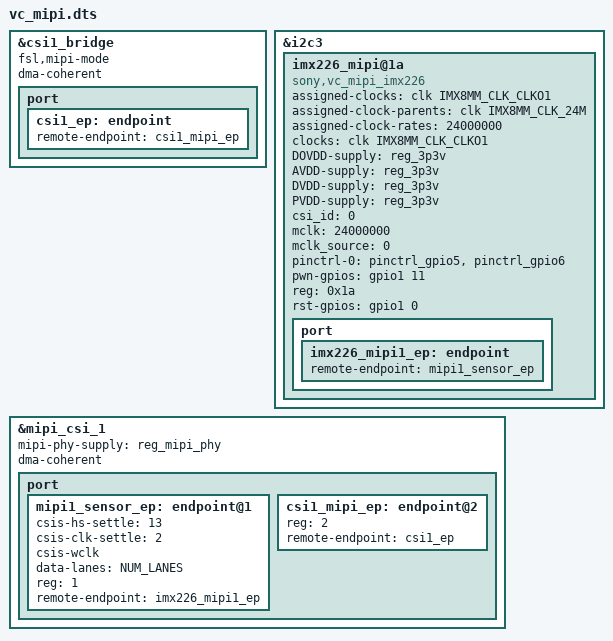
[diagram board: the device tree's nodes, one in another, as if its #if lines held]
/dts-v1/;

//#include "imx8mm-verdin.dtsi"
//#include "imx8mm-verdin-wifi.dtsi"
//#include "imx8mm-verdin-dev.dtsi"
#include "imx8mm-verdin-wifi-v1.1-dahlia.dts"

// Select VC MIPI driver - enable 1 driver only !
#define TORADEX_OV5640      0    /* CCC - Enable Toradex OV5640 driver                     */
#define VC_MIPI_OV9281      0    /* CCC - Enable VC MIPI OV9281 driver                     */
#define VC_MIPI_IMX_296_297 0    /* CCC - Enable VC MIPI IMX296,297 driver                 */
#define VC_MIPI_IMX         1    /* CCC - Enable VC MIPI IMX driver: all other IMX sensors */
// #define VC_MIPI_IMX226      0    /* CCC - Enable VC MIPI IMX226 driver      */

#define SCREENING_EAGLE_IMX258  0    /* CCC - Enable Screening Eagle IMX258 driver */


// / {
//     model = "Toradex Verdin iMX8M Mini WB on Verdin Development Board";
//     compatible = "toradex,verdin-imx8mm-wifi-dev",
//              "toradex,verdin-imx8mm-wifi",
//              "toradex,verdin-imx8mm",
//              "fsl,imx8mm";
// };


&csi1_bridge {
    fsl,mipi-mode;
    dma-coherent;
    status = "okay";

    port {
        csi1_ep: endpoint {
            remote-endpoint = <&csi1_mipi_ep>;
        };
    };
};

//----------------------------------------------------------------------------------
#if TORADEX_OV5640      /* [[[ - Toradex OV5640 driver  */
//----------------------------------------------------------------------------------
/* Verdin I2C_4_CSI */
&i2c3 {
    #address-cells = <1>;
    #size-cells = <0>;
    status = "okay";

    ov5640_mipi@3c {
        assigned-clocks = <&clk IMX8MM_CLK_CLKO1>;
        assigned-clock-parents = <&clk IMX8MM_CLK_24M>;
        assigned-clock-rates = <24000000>;
        compatible = "ovti,ov5640_mipi";
        clock-names = "csi_mclk";
        clocks = <&clk IMX8MM_CLK_CLKO1>;
        DOVDD-supply = <&reg_3p3v>;
        AVDD-supply = <&reg_3p3v>;
        DVDD-supply = <&reg_3p3v>;
        PVDD-supply = <&reg_3p3v>;
        csi_id = <0>;
        mclk = <24000000>;
        mclk_source = <0>;
        pinctrl-names = "default";
        pinctrl-0 = <&pinctrl_gpio5>, <&pinctrl_gpio6>;
        pwn-gpios = <&gpio1 11 GPIO_ACTIVE_HIGH>;
        reg = <0x3c>;
        rst-gpios = <&gpio1 0 GPIO_ACTIVE_HIGH>;
        status = "okay";

        port {
            ov5640_mipi1_ep: endpoint {
                remote-endpoint = <&mipi1_sensor_ep>;
            };
        };
    };
};

&mipi_csi_1 {
    mipi-phy-supply = <&reg_mipi_phy>;
    dma-coherent;
    status = "okay";

    port {
        #address-cells = <1>;
        #size-cells = <0>;

        mipi1_sensor_ep: endpoint@1 {
            csis-hs-settle = <13>;
            csis-clk-settle = <2>;
            csis-wclk;
            data-lanes = <2>;
            reg = <1>;
            remote-endpoint = <&ov5640_mipi1_ep>;
        };

        csi1_mipi_ep: endpoint@2 {
            reg = <2>;
            remote-endpoint = <&csi1_ep>;
        };
    };
};

//----------------------------------------------------------------------------------
#elif VC_MIPI_OV9281      /* ]]] [[[ - VC MIPI OV9281 driver */
//----------------------------------------------------------------------------------
&i2c3 {
    #address-cells = <1>;
    #size-cells = <0>;
    status = "okay";

    ov9281_mipi@60 {
        assigned-clocks = <&clk IMX8MM_CLK_CLKO1>;
        assigned-clock-parents = <&clk IMX8MM_CLK_24M>;
        assigned-clock-rates = <24000000>;
        compatible = "omnivision,vc_mipi_ov9281";
//        compatible = "ov,ov9281";
        clock-names = "csi_mclk";
        clocks = <&clk IMX8MM_CLK_CLKO1>;
        DOVDD-supply = <&reg_3p3v>;
        AVDD-supply = <&reg_3p3v>;
        DVDD-supply = <&reg_3p3v>;
        PVDD-supply = <&reg_3p3v>;
        csi_id = <0>;
        mclk = <24000000>;
        mclk_source = <0>;
        pinctrl-names = "default";
        pinctrl-0 = <&pinctrl_gpio5>, <&pinctrl_gpio6>;
        pwn-gpios = <&gpio1 11 GPIO_ACTIVE_HIGH>;
        reg = <0x60>;
        rst-gpios = <&gpio1 0 GPIO_ACTIVE_HIGH>;
        status = "okay";

        port {
            ov9281_mipi1_ep: endpoint {
                remote-endpoint = <&mipi1_sensor_ep>;
            };
        };
    };
};

&mipi_csi_1 {
    mipi-phy-supply = <&reg_mipi_phy>;
    dma-coherent;
    status = "okay";

    port {
        #address-cells = <1>;
        #size-cells = <0>;

        mipi1_sensor_ep: endpoint@1 {
            csis-hs-settle = <13>;
            csis-clk-settle = <2>;
            csis-wclk;
            data-lanes = <2>;
            reg = <1>;
            remote-endpoint = <&ov9281_mipi1_ep>;
        };

        csi1_mipi_ep: endpoint@2 {
            reg = <2>;
            remote-endpoint = <&csi1_ep>;
        };
    };
};

//----------------------------------------------------------------------------------
#elif VC_MIPI_IMX_296_297       /* ]]] [[[ - VC MIPI IMX296,297 driver  */
//----------------------------------------------------------------------------------
#define NUM_LANES  1    /* CCC - # of lanes: 1, 2 or 4  */
&i2c3 {
    #address-cells = <1>;
    #size-cells = <0>;
    status = "okay";

    imx_mipi@1a {
        assigned-clocks = <&clk IMX8MM_CLK_CLKO1>;
        assigned-clock-parents = <&clk IMX8MM_CLK_24M>;
        assigned-clock-rates = <24000000>;   // original

        compatible = "sony,vc_mipi_imx";
        clock-names = "csi_mclk";
        clocks = <&clk IMX8MM_CLK_CLKO1>;
        DOVDD-supply = <&reg_3p3v>;
        AVDD-supply = <&reg_3p3v>;
        DVDD-supply = <&reg_3p3v>;
        PVDD-supply = <&reg_3p3v>;
        csi_id = <0>;
        mclk = <24000000>;
        mclk_source = <0>;
        pinctrl-names = "default";
        pinctrl-0 = <&pinctrl_gpio5>, <&pinctrl_gpio6>;
        pwn-gpios = <&gpio1 11 GPIO_ACTIVE_HIGH>;
        reg = <0x1a>;
        rst-gpios = <&gpio1 0 GPIO_ACTIVE_HIGH>;
        status = "okay";

        port {
            imx_mipi1_ep: endpoint {
                remote-endpoint = <&mipi1_sensor_ep>;
            };
        };
    };
};

&mipi_csi_1 {
    mipi-phy-supply = <&reg_mipi_phy>;
//    clock-frequency = <333000000>;  // default
    dma-coherent;
    status = "okay";

    port {
        #address-cells = <1>;
        #size-cells = <0>;

        mipi1_sensor_ep: endpoint@1 {
            csis-hs-settle = <13>;
            csis-clk-settle = <2>;
            csis-wclk;
            data-lanes = <NUM_LANES>;
            reg = <1>;
            remote-endpoint = <&imx_mipi1_ep>;
        };

        csi1_mipi_ep: endpoint@2 {
            reg = <2>;
            remote-endpoint = <&csi1_ep>;
        };
    };
};

//----------------------------------------------------------------------------------
#elif VC_MIPI_IMX226        /* ]]] [[[ - VC MIPI IMX226 driver */
//----------------------------------------------------------------------------------
#define NUM_LANES  2    /* CCC - # of lanes: 2 or 4  */
&i2c3 {
    #address-cells = <1>;
    #size-cells = <0>;
    status = "okay";

    imx226_mipi@1a {
        assigned-clocks = <&clk IMX8MM_CLK_CLKO1>;
        assigned-clock-parents = <&clk IMX8MM_CLK_24M>;
        assigned-clock-rates = <24000000>;

//        assigned-clock-rates = <266000000>, <333000000>, <66000000>;
//        assigned-clock-rates = <266000000>, <150000000>, <66000000>;  // decreased rate, low FPS
//        assigned-clock-rates = <266000000>, <400000000>, <66000000>;  // ???

//        assigned-clock-rates = <133000000>, <100000000>, <66000000>;
//        assigned-clock-rates = <200000000>, <333000000>, <66000000>;

        compatible = "sony,vc_mipi_imx226";
        clock-names = "csi_mclk";
        clocks = <&clk IMX8MM_CLK_CLKO1>;
        DOVDD-supply = <&reg_3p3v>;
        AVDD-supply = <&reg_3p3v>;
        DVDD-supply = <&reg_3p3v>;
        PVDD-supply = <&reg_3p3v>;
        csi_id = <0>;
        mclk = <24000000>;
        mclk_source = <0>;
        pinctrl-names = "default";
        pinctrl-0 = <&pinctrl_gpio5>, <&pinctrl_gpio6>;
        pwn-gpios = <&gpio1 11 GPIO_ACTIVE_HIGH>;
        reg = <0x1a>;
        rst-gpios = <&gpio1 0 GPIO_ACTIVE_HIGH>;
        status = "okay";

        port {
            imx226_mipi1_ep: endpoint {
                remote-endpoint = <&mipi1_sensor_ep>;
            };
        };
    };
};

&mipi_csi_1 {
    mipi-phy-supply = <&reg_mipi_phy>;
//    clock-frequency = <166000000>;
//    clock-frequency = <333000000>;   // default
//      clock-frequency = <400000000>;
//    clock-frequency = <800000000>;
    dma-coherent;
    status = "okay";

    port {
        #address-cells = <1>;
        #size-cells = <0>;

        mipi1_sensor_ep: endpoint@1 {
            csis-hs-settle = <13>;
            csis-clk-settle = <2>;
            csis-wclk;
            data-lanes = <NUM_LANES>;
            reg = <1>;
            remote-endpoint = <&imx226_mipi1_ep>;
        };

        csi1_mipi_ep: endpoint@2 {
            reg = <2>;
            remote-endpoint = <&csi1_ep>;
        };
    };
};

//----------------------------------------------------------------------------------
#elif VC_MIPI_IMX        /* ]]] [[[ - VC MIPI IMX driver - all other IMX sesnors  */
//----------------------------------------------------------------------------------
#define NUM_LANES  2    /* CCC - # of lanes: 2 or 4  */
&i2c3 {
    #address-cells = <1>;
    #size-cells = <0>;
    status = "okay";

    imx_mipi@1a {
        assigned-clocks = <&clk IMX8MM_CLK_CLKO1>;
        assigned-clock-parents = <&clk IMX8MM_CLK_24M>;
        assigned-clock-rates = <24000000>;   // original

//      assigned-clock-rates = <133000000>;
//      assigned-clock-rates = <266000000>;  // ???
//      assigned-clock-rates = <480000000>;
//      assigned-clock-rates = <480000000>, <333000000>, <66000000>;

//        assigned-clock-rates = <266000000>, <333000000>, <66000000>;
//        assigned-clock-rates = <266000000>, <150000000>, <66000000>;  // decreased rate, low FPS
//        assigned-clock-rates = <266000000>, <400000000>, <66000000>;

//        assigned-clock-rates = <133000000>, <100000000>, <66000000>;   // ???
//        assigned-clock-rates = <200000000>, <333000000>, <66000000>;

        compatible = "sony,vc_mipi_imx";
        clock-names = "csi_mclk";
        clocks = <&clk IMX8MM_CLK_CLKO1>;
        DOVDD-supply = <&reg_3p3v>;
        AVDD-supply = <&reg_3p3v>;
        DVDD-supply = <&reg_3p3v>;
        PVDD-supply = <&reg_3p3v>;
        csi_id = <0>;
        mclk = <24000000>;
        mclk_source = <0>;
        pinctrl-names = "default";
        pinctrl-0 = <&pinctrl_gpio5>, <&pinctrl_gpio6>;
        pwn-gpios = <&gpio1 11 GPIO_ACTIVE_HIGH>;
        reg = <0x1a>;
        rst-gpios = <&gpio1 0 GPIO_ACTIVE_HIGH>;
        status = "okay";

        port {
            imx_mipi1_ep: endpoint {
                remote-endpoint = <&mipi1_sensor_ep>;
            };
        };
    };
};

&mipi_csi_1 {
    mipi-phy-supply = <&reg_mipi_phy>;
    dma-coherent;
//    clock-frequency = <166000000>;
//    clock-frequency = <240000000>;  // bad
//    clock-frequency = <333000000>;  // default
//    clock-frequency = <400000000>;
//    clock-frequency = <666000000>;
//    clock-frequency = <800000000>;  // fails

//    clock-frequency = <500000000>;
    status = "okay";

    port {
        #address-cells = <1>;
        #size-cells = <0>;

        mipi1_sensor_ep: endpoint@1 {
            csis-hs-settle = <13>;
            csis-clk-settle = <2>;
            csis-wclk;
            data-lanes = <NUM_LANES>;
            reg = <1>;
            remote-endpoint = <&imx_mipi1_ep>;
        };

        csi1_mipi_ep: endpoint@2 {
            reg = <2>;
            remote-endpoint = <&csi1_ep>;
        };
    };
};
//----------------------------------------------------------------------------------
#elif SCREENING_EAGLE_IMX258   /* ]]] [[[ - Screening Eagle IMX258 driver */
//----------------------------------------------------------------------------------
#define NUM_LANES  2    /* CCC - # of lanes: 2 or 4  */
&i2c3 {
    #address-cells = <1>;
    #size-cells = <0>;
    status = "okay";

    imx258_mipi@1a {
        assigned-clocks = <&clk IMX8MM_CLK_CLKO1>;
        assigned-clock-parents = <&clk IMX8MM_CLK_24M>;
        assigned-clock-rates = <24000000>;   // original

//      assigned-clock-rates = <133000000>;
//      assigned-clock-rates = <266000000>;  // ???
//      assigned-clock-rates = <480000000>;
//      assigned-clock-rates = <480000000>, <333000000>, <66000000>;

//        assigned-clock-rates = <266000000>, <333000000>, <66000000>;
//        assigned-clock-rates = <266000000>, <150000000>, <66000000>;  // decreased rate, low FPS
//        assigned-clock-rates = <266000000>, <400000000>, <66000000>;

//        assigned-clock-rates = <133000000>, <100000000>, <66000000>;   // ???
//        assigned-clock-rates = <200000000>, <333000000>, <66000000>;

        compatible = "sony,imx258";
        clock-names = "csi_mclk";
        clocks = <&clk IMX8MM_CLK_CLKO1>;
        DOVDD-supply = <&reg_3p3v>;
        AVDD-supply = <&reg_3p3v>;
        DVDD-supply = <&reg_3p3v>;
        PVDD-supply = <&reg_3p3v>;
        csi_id = <0>;
        mclk = <24000000>;
        mclk_source = <0>;
        pinctrl-names = "default";
        pinctrl-0 = <&pinctrl_gpio5>, <&pinctrl_gpio6>;
        pwn-gpios = <&gpio1 11 GPIO_ACTIVE_HIGH>;
        reg = <0x1a>;
        rst-gpios = <&gpio1 0 GPIO_ACTIVE_HIGH>;
        status = "okay";

        port {
            imx258_mipi1_ep: endpoint {
                remote-endpoint = <&mipi1_sensor_ep>;
            };
        };
    };
};

&mipi_csi_1 {
    mipi-phy-supply = <&reg_mipi_phy>;
//    clock-frequency = <166000000>;
//    clock-frequency = <240000000>;  // bad
//    clock-frequency = <333000000>;  // default
//    clock-frequency = <400000000>;
//    clock-frequency = <666000000>;
//    clock-frequency = <800000000>;  // fails
    dma-coherent;
    status = "okay";

    port {
        #address-cells = <1>;
        #size-cells = <0>;

        mipi1_sensor_ep: endpoint@1 {
            csis-hs-settle = <13>;
            csis-clk-settle = <2>;
            csis-wclk;
            data-lanes = <NUM_LANES>;
            reg = <1>;
            remote-endpoint = <&imx258_mipi1_ep>;
        };

        csi1_mipi_ep: endpoint@2 {
            reg = <2>;
            remote-endpoint = <&csi1_ep>;
        };
    };
};
#endif  /* ]]] */

